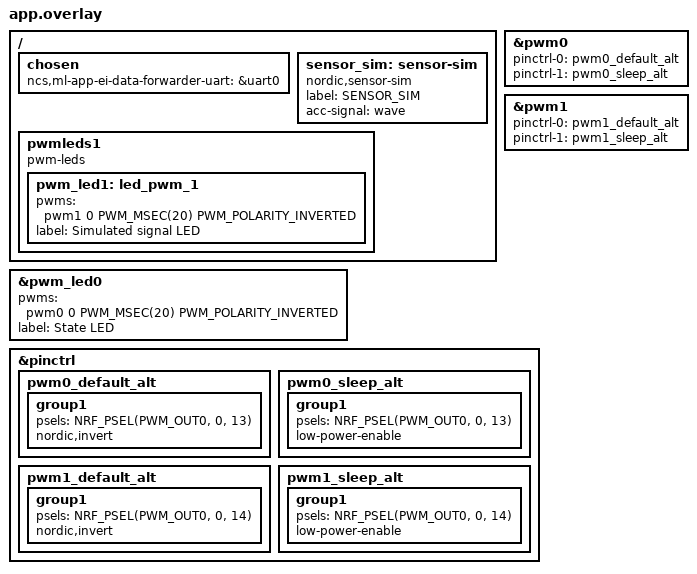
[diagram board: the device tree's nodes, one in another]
/ {
	chosen {
		ncs,ml-app-ei-data-forwarder-uart = &uart0;
	};

	sensor_sim: sensor-sim {
		compatible = "nordic,sensor-sim";
		label = "SENSOR_SIM";
		acc-signal = "wave";
	};

	pwmleds1 {
		compatible = "pwm-leds";
		status = "okay";

		pwm_led1: led_pwm_1 {
			status = "okay";
			pwms = <&pwm1 0 PWM_MSEC(20) PWM_POLARITY_INVERTED>;
			label = "Simulated signal LED";
		};
	};
};

&pwm0 {
	status = "okay";
	pinctrl-0 = <&pwm0_default_alt>;
	pinctrl-1 = <&pwm0_sleep_alt>;
	pinctrl-names = "default", "sleep";
};

&pwm1 {
	status = "okay";
	pinctrl-0 = <&pwm1_default_alt>;
	pinctrl-1 = <&pwm1_sleep_alt>;
	pinctrl-names = "default", "sleep";
};

&pwm_led0 {
	status = "okay";
	pwms = <&pwm0 0 PWM_MSEC(20) PWM_POLARITY_INVERTED>;
	label = "State LED";
};

&pinctrl {
	pwm0_default_alt: pwm0_default_alt {
		group1 {
			psels = <NRF_PSEL(PWM_OUT0, 0, 13)>;
			nordic,invert;
		};
	};

	pwm0_sleep_alt: pwm0_sleep_alt {
		group1 {
			psels = <NRF_PSEL(PWM_OUT0, 0, 13)>;
			low-power-enable;
		};
	};

	pwm1_default_alt: pwm1_default_alt {
		group1 {
			psels = <NRF_PSEL(PWM_OUT0, 0, 14)>;
			nordic,invert;
		};
	};

	pwm1_sleep_alt: pwm1_sleep_alt {
		group1 {
			psels = <NRF_PSEL(PWM_OUT0, 0, 14)>;
			low-power-enable;
		};
	};

};
